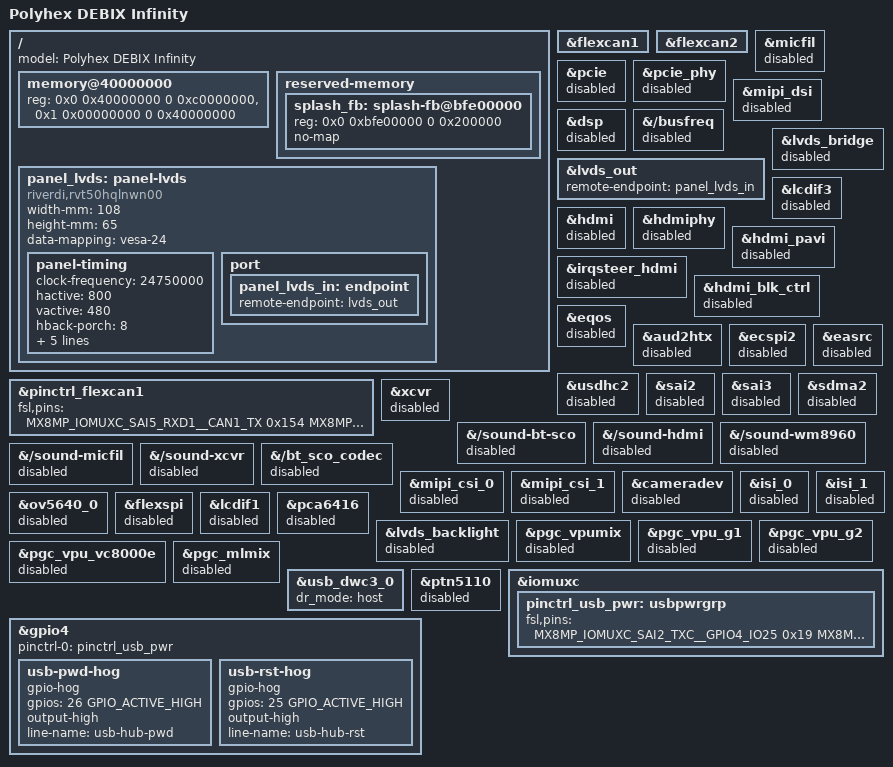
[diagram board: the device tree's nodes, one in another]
// SPDX-License-Identifier: (GPL-2.0+ OR MIT)
/*
 * imx8mp-debix.dts — Polyhex DEBIX Infinity (EMB-IMX8MP-06) 用製品 DT
 *
 * 根拠は工場イメージ (Ubuntu 20.04 + 5.10 NXP BSP) の実行中 FDT との突き合わせ:
 *  - 実行中 FDT = /boot/imx8mp-evk.dtb (= imx8mp-debix-core-board.dtb と同一物)
 *  - 吸い出し: 工場イメージの /sys/firmware/fdt (実体 /boot/imx8mp-evk.dtb)
 *  - 差分分析: docs/imx8mp-debix-bringup/02-dts-delta.md
 *
 * EVK との差分:
 *  - flexcan1: pinmux を SPDIF_TX/RX → SAI5_RXD1/RXD2 (J2 ヘッダー Pin31/33) に変更。
 *  - flexcan2: 有効化。pin group (SAI5_RXD3/MCLK = J2 Pin35/37) は EVK 定義と工場で一致。
 *  - CAN トランシーバはボードに無い (J2 に出るのは 3.3V TXD/RXD)。工場 DT にも
 *    xceiver-supply が無く、EVK の standby GPIO (gpio5_5/gpio4_27) や I/O エキスパンダ
 *    (pca6416) を DEBIX で触らないよう supply/assert-gpios を削除する。
 *  - micfil (PDM): EVK で flexcan2 と SAI5 パッドを取り合う相手。DEBIX では PDM
 *    マイク未配線なので disabled (EVK の「can2 pin conflict with pdm」コメント参照)。
 *  - pcie/mipi_dsi/dsp: DEBIX では未使用 (PCIe は 19pin FPC のみ、表示は LVDS、
 *    DSP は使わない)。工場 DT も disabled — 未接続プローブのエラーと起動遅延を避ける。
 *  - 表示: J10 の LVDS0 → 変換基板 (debix-hat/lvds-adapter) → Riverdi RVT50HQLNWN00
 *    (800x480)。経路は lcdif2 → LDB ch0 → LVDS PHY → panel-lvds。HDMI (lcdif3 + DW-HDMI
 *    一式) は止める。
 *  - uart4: EVK 既定の disabled のまま = M7 コンソール予約 (01-m7.md)。
 *  - WiFi (88W8987 / usdhc1): 不使用 → EVK 既定の disabled のまま。
 */

#include "imx8mp-evk.dts"

/ {
	model = "Polyhex DEBIX Infinity";

	/*
	 * DEBIX Infinity D4E32 の DRAM は 4GB = 3GB @0x40000000 + 1GB @0x100000000
	 * (U-Boot の PHYS_SDRAM/PHYS_SDRAM_2 と同じ)。EVK dts は 6GB (3GB + 3GB) を
	 * 宣言しており、U-Boot proper 経由なら fdt_fixup_memory_banks が直すが、
	 * falcon 経路は DTB をそのまま使うため、上位 1GB (0x140000000〜) が存在しない
	 * RAM としてカーネルに見えていた (memtester 2GB でバス停止 → WDT リセット、
	 * 2026-09-08)。ここで正しい 2 バンクに固定する。
	 */
	memory@40000000 {
		reg = <0x0 0x40000000 0 0xc0000000>,
		      <0x1 0x00000000 0 0x40000000>;
	};

	reserved-memory {
		/*
		 * SPL スプラッシュのフレームバッファ (0005 パッチの SPLASH_FB_ADDR、
		 * 800x480x4 = 1.5MB)。カーネルは表示を養子縁組して weston の初回 flip まで
		 * この FB を走査し続けるので、no-map で触らせない (以前は falcon の
		 * bootargs mem=2042M で隠していたが、それは 4GB 構成を壊す)。
		 */
		splash_fb: splash-fb@bfe00000 {
			reg = <0x0 0xbfe00000 0 0x200000>;
			no-map;
		};
	};
};

&flexcan1 {
	/delete-property/ xceiver-supply;
};

&pinctrl_flexcan1 {
	fsl,pins = <
		MX8MP_IOMUXC_SAI5_RXD1__CAN1_TX		0x154
		MX8MP_IOMUXC_SAI5_RXD2__CAN1_RX		0x154
	>;
};

&flexcan2 {
	/delete-property/ xceiver-supply;
	/delete-property/ pinctrl-assert-gpios;
	status = "okay";
};

&micfil {
	status = "disabled";
};

&pcie {
	status = "disabled";
};

&pcie_phy {
	status = "disabled";
};

&mipi_dsi {
	status = "disabled";
};

&dsp {
	status = "disabled";
};

/* busfreq (DDR 低速バスモード) は使わない:
 *  - キオスク用途で表示は常時稼働 = 低速モードに入れる局面が実質無い
 *  - SPL スプラッシュが LCDIF 走査中のままカーネルへ渡す構成では、ブート
 *    途中の「ddrc freq set to low bus mode」遷移がアクティブな表示 DMA と
 *    衝突してカーネルが恒久ハングする (実測)。無効化で遷移自体を消す */
&{/busfreq} {
	status = "disabled";
};

/* ===== 表示: LVDS パネル (J10 の LVDS0) =====
 * lcdif2 → LDB の ch0 → LVDS PHY → panel-lvds。ldb/ldb_phy/lcdif2/lvds-channel@0 は
 * EVK の dts が okay にしているので、ここでは出口の先を IT6263 からパネルに付け替える。
 * DT とカーネルの cfg は必ずセット (slim-imx8mp.cfg の DRM_IMX8MP_LDB・DRM_PANEL_LVDS):
 * ノードが有効でドライバが無いと imx-drm のコンポーネント束ねが ldb を待ち続け、
 * display-subsystem (= /dev/dri の表示カード) ごと現れず weston が「no drm device found」
 * で死ぬ (2026-09-02 実測)。
 */
/ {
	/*
	 * Riverdi RVT50HQLNWN00: 5 インチ 800x480、VESA 24 ビット (変換基板で SELB を High、
	 * L/R・U/D も High = 反転なし)。タイミングはデータシート (DS_RVT50HQLNWN00 Rev.1.0)
	 * の標準値。クロックだけ 25 MHz ではなく 24.75 MHz (= video_pll1 1039.5 MHz / 42):
	 * LDB はピクセルクロックのちょうど 7 倍 (173.25 MHz = / 6) が要り、25 MHz だと同じ
	 * PLL から 7 倍の比で割れない。パネルの範囲は 23〜27 MHz で、更新は約 60.4 Hz。
	 * NXP の LDB のドライバは 1 チャネルのときクロックを 74.25 MHz に書き換えるので、
	 * パッチ 0014 でパネルのときは書き換えないようにしている (無いと約 3 倍のクロックで
	 * 真っ黒になる。2026-11-10 実測)。
	 *
	 * 電源とバックライトは変換基板が J10 の 5 V から作る (3.3 V の LDO と LED の定電流)。
	 * 5 V は J10 の負荷スイッチの EN (回路図の LVDS_PWR_EN = GPIO4_IO25) で入り、
	 * GPIO4_IO25 は下の usb-rst-hog が起動時から High に保つので power-supply は書かない。
	 * RESET/STBYB は変換基板の RC で順番に上がり、バックライトの制御線も J10 に無い。
	 */
	panel_lvds: panel-lvds {
		compatible = "riverdi,rvt50hqlnwn00", "panel-lvds";
		width-mm = <108>;
		height-mm = <65>;
		data-mapping = "vesa-24";

		panel-timing {
			clock-frequency = <24750000>;
			hactive = <800>;
			vactive = <480>;
			hback-porch = <8>;
			hfront-porch = <8>;
			hsync-len = <4>;
			vback-porch = <8>;
			vfront-porch = <8>;
			vsync-len = <4>;
		};

		port {
			panel_lvds_in: endpoint {
				remote-endpoint = <&lvds_out>;
			};
		};
	};
};

&lvds_out {
	remote-endpoint = <&panel_lvds_in>;
};

/* EVK の LVDS→HDMI ブリッジ (IT6263)。DEBIX に無い (ドライバも slim で外してある) */
&lvds_bridge {
	status = "disabled";
};

/* HDMI は使わない。lcdif3 と DW-HDMI・PHY・PVI、HDMI の割り込みと電源の区画
 * (hdmi_blk_ctrl) を止める。hdmi_blk_ctrl の電源の区画と irqsteer_hdmi を使うのは
 * ここで止める HDMI のノードだけ (imx8mp.dtsi)。 */
&lcdif3 {
	status = "disabled";
};

&hdmi {
	status = "disabled";
};

&hdmiphy {
	status = "disabled";
};

&hdmi_pavi {
	status = "disabled";
};

&irqsteer_hdmi {
	status = "disabled";
};

&hdmi_blk_ctrl {
	status = "disabled";
};

/* ===== EVK 遺産の死にノード掃除 (2026-09-03、起動時間: udev/probe 削減) =====
 * DEBIX で消費者がいない EVK 有効化ノードを落とす。効果は
 * ① probe 時間 (eqos 0.2s+PHY 等) ② coldplug の uevent 数 ③ dmesg ノイズ
 * (ov5640/pca953x/csis の probe エラー消滅)。根拠: 実配線 (02-dts-delta.md)
 * と実機 dmesg。カーネル config 側は既に SND/V4L2 等を削っており、
 * これはその DT 側の対 (ノードだけ残っていた)。 */

/* 第 2 イーサネット (eqos/eth1): 未配線 (実機で down/リンクなし) */
&eqos {
	status = "disabled";
};

/* オーディオ一式 (無音キオスク。コーデックも未実装) */
&aud2htx {
	status = "disabled";
};

/* audio_blk_ctrl (30e20000): 無効化すると起動ハング (2026-09-14 実測、slot A tryboot が
 * カーネル初期で停止 → A/B フォールバックで回復)。AudioMIX は電源ドメイン/クロック
 * provider で、消費者を全て disabled にしても本体を落とすと genpd/clk 側で詰まる。
 * probe ~12ms は惜しいが有効のまま残す。 */

/* ecspi2 (30830000): DEBIX では未配線 (DTS に子ノード無し。8MM の MCP2515 相当は
 * 8MP では M7 の FlexCAN。SPI-NOR も無し = MTD off)。probe を消す (~14ms) */
&ecspi2 {
	status = "disabled";
};

/* usdhc2 (30b50000): SD カードスロット。製品は eMMC (usdhc3) 起動で、稼働 Linux が
 * SD をマウントする用途は無い (SD のベンダ OS 起動は ROM が DIP で行うので本ノード
 * 無効化とは無関係)。probe を消す (open-issues #7、initcall_debug 実測 ~32ms) */
&usdhc2 {
	status = "disabled";
};

&easrc {
	status = "disabled";
};

&sai2 {
	status = "disabled";
};

&sai3 {
	status = "disabled";
};

&sdma2 {
	status = "disabled";
};

&xcvr {
	status = "disabled";
};

&{/sound-bt-sco} {
	status = "disabled";
};

&{/sound-hdmi} {
	status = "disabled";
};

&{/sound-wm8960} {
	status = "disabled";
};

&{/sound-micfil} {
	status = "disabled";
};

&{/sound-xcvr} {
	status = "disabled";
};

&{/bt_sco_codec} {
	status = "disabled";
};

/* カメラ一式 (未搭載。ov5640 は毎ブート probe エラーを吐いていた) */
&mipi_csi_0 {
	status = "disabled";
};

&mipi_csi_1 {
	status = "disabled";
};

&cameradev {
	status = "disabled";
};

&isi_0 {
	status = "disabled";
};

&isi_1 {
	status = "disabled";
};

&ov5640_0 {
	status = "disabled";
};

/* FlexSPI: NOR 非搭載 (MTD もカーネルから削除済み) */
&flexspi {
	status = "disabled";
};

/* 表示に使わない CRTC (表示は lcdif2=LVDS のみ。lcdif1=DSI は接続先を
 * disabled 済みで、crtc だけ probe されて uevent を増やしていた) */
&lcdif1 {
	status = "disabled";
};

/* I/O エキスパンダ (EVK の CSI/LVDS 用 pca6416)。DEBIX に非実装で
 * 毎ブート probe -11 を吐いていた */
&pca6416 {
	status = "disabled";
};

/* LVDS バックライト (EVK 遺産)。バックライトは変換基板の定電流で 5 V と連動して
 * 点き、この PWM は未配線。systemd-backlight@ が毎ブート failed になる発生源 */
&lvds_backlight {
	status = "disabled";
};

/* Quad Lite でヒューズアウトされている VPU/NPU の GPC 電源ドメイン。
 * pgc_vpumix (power-domain@8) は「imx-pgc-domain.8: failed to command PGC」
 * を毎ブート 3 連発し (open-issues 旧 #8 の正体)、子の g1/g2/vc8000e
 * (@11/12/13) は永久 deferred でぶら下がっていた */
&pgc_vpumix {
	status = "disabled";
};

&pgc_vpu_g1 {
	status = "disabled";
};

&pgc_vpu_g2 {
	status = "disabled";
};

&pgc_vpu_vc8000e {
	status = "disabled";
};

&pgc_mlmix {
	status = "disabled";
};

/*
 * USB1 (DWN_USB1 = OTG 可の Type-A、UUU で使う口) を host 固定にする。
 * EVK は Type-C コントローラ (PTN5110) の usb-role-switch で host/device を決めるが、
 * DEBIX の Type-C は電源専用で CONFIG_USB_TCPC も無効のため役割が決まらず、ポートが
 * 死んだままになる (2026-09-21 実測: LTE ドングルが列挙されず LED も点かない)。
 * UUU (BootROM/SPL の SDP) は Linux の DT に依存しないので eMMC 復旧には影響しない。
 * port/endpoint ノードは ptn5110 側からの参照が残るため削除せず、role switch だけ外す。
 */
&usb_dwc3_0 {
	dr_mode = "host";
	/delete-property/ usb-role-switch;
	/delete-property/ role-switch-default-mode;
};

&ptn5110 {
	status = "disabled";
};

/*
 * Type-A ポートの給電。ベンダー DTS/カーネルは dwc3 の独自ハック (hub-pwd-gpio = GPIO4_IO26 /
 * hub-reset-gpio = GPIO4_IO25) で起動時に両方 High にしていた。うちは gpio-hog で同じ状態を
 * 起動時に作る。Low/浮きのままだと Type-A に 5V が出ず、挿したデバイスは LED も点かない
 * (2026-09-21 実測: High にして ~20s で LTE ドングルが列挙)。SAI2 は disabled でパッドは空き。
 * なお GPIO4_IO25 は回路図では J10 の 5 V の負荷スイッチの EN (LVDS_PWR_EN) でもあり、
 * これが High なので LVDS パネルにも起動時から 5 V が入る (上の panel-lvds 参照)。
 */
&iomuxc {
	pinctrl_usb_pwr: usbpwrgrp {
		fsl,pins = <
			MX8MP_IOMUXC_SAI2_TXC__GPIO4_IO25	0x19
			MX8MP_IOMUXC_SAI2_TXD0__GPIO4_IO26	0x19
		>;
	};
};

&gpio4 {
	pinctrl-names = "default";
	pinctrl-0 = <&pinctrl_usb_pwr>;

	usb-pwd-hog {
		gpio-hog;
		gpios = <26 GPIO_ACTIVE_HIGH>;
		output-high;
		line-name = "usb-hub-pwd";
	};

	usb-rst-hog {
		gpio-hog;
		gpios = <25 GPIO_ACTIVE_HIGH>;
		output-high;
		line-name = "usb-hub-rst";
	};
};
